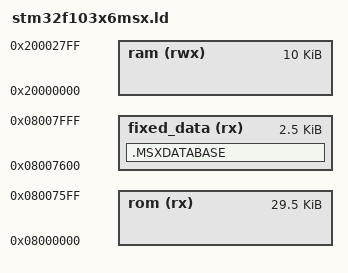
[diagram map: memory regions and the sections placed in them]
/*
 *
 * This was edited to put the specific table of conversion in fixed_data, with size up of 3KB at the address 0x0800F400.
 * So it made feasible to implement routines inside to load the new table.
 * 
 * Procedure to load the new table:
 * 1) Connect a serial adapter to USART1 (5V tolerant);
 * 2) Turn it on with the PS/2 keyboard UNPLUGGED;
 * 3) Serial commmunication parameters:
 *	- 115200 bps;
 *	- 8 bits;
 *	- no parity;
 *	- 1 stop bit.
 *
 * Just send the intel hex file generated by excel after you see:
 * "Please send the new MSX Translate Table File in Intel Hex format update Flash memory!"
 *
 *
 *
 *
 * This file was part of the libopencm3 project.
 * Copyright (C) 2015 Karl Palsson <karlp@tweak.net.au>
 *
 * This library is free software: you can redistribute it and/or modify
 * it under the terms of the GNU Lesser General Public License as published by
 * the Free Software Foundation, either version 3 of the License, or
 * (at your option) any later version.
 *
 * This library is distributed in the hope that it will be useful,
 * but WITHOUT ANY WARRANTY; without even the implied warranty of
 * MERCHANTABILITY or FITNESS FOR A PARTICULAR PURPOSE.  See the
 * GNU Lesser General Public License for more details.
 *
 * You should have received a copy of the GNU Lesser General Public License
 * along with this library.  If not, see <http://www.gnu.org/licenses/>.
 */

/* Linker script for STM32F103x6, 32K flash, 10K RAM. */

/* Define memory regions. */
MEMORY
{
	ram (rwx)		: ORIGIN = 0x20000000, LENGTH = 10K
	rom (rx)		: ORIGIN = 0x08000000, LENGTH = 30208
	fixed_data (rx)	: ORIGIN = 0x08007600, LENGTH = 2560
}

SECTIONS
{
	.MSXDATABASE : {
		*(MSXDATABASE)
	} >fixed_data
}

/* Include the common ld script. */
INCLUDE cortex-m-generic.ld
